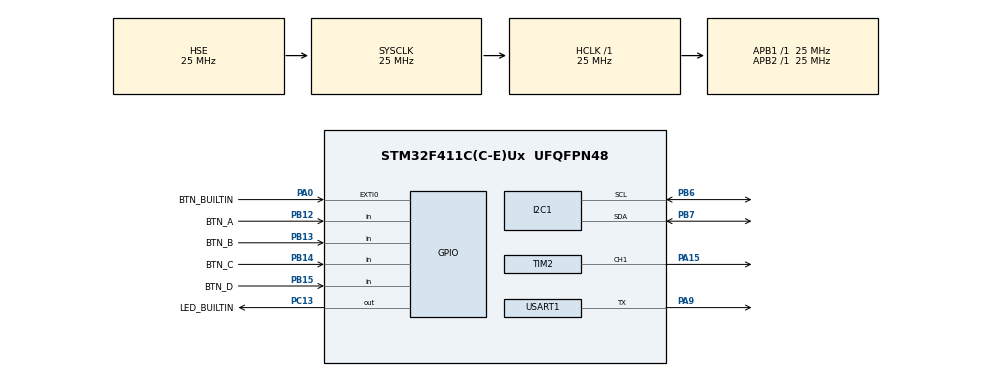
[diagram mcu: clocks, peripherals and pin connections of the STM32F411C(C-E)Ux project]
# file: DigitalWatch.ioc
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FREERTOS.INCLUDE_xTaskAbortDelay=1
FREERTOS.Tasks01=defaultTask,24,128,StartDefaultTask,Default,NULL,Dynamic,NULL,NULL
FREERTOS.configGENERATE_RUN_TIME_STATS=1
FREERTOS.configRECORD_STACK_HIGH_ADDRESS=1
FREERTOS.configTIMER_TASK_PRIORITY=4
FREERTOS.configTIMER_TASK_STACK_DEPTH=256
FREERTOS.configUSE_IDLE_HOOK=0
FREERTOS.configUSE_PREEMPTION=0
FREERTOS.configUSE_STATS_FORMATTING_FUNCTIONS=1
Mcu.Family=STM32F4
Mcu.Name=STM32F411C(C-E)Ux
Mcu.Package=UFQFPN48
NVIC.EXTI0_IRQn=true\:5\:0\:false\:false\:true\:true\:true\:true\:true
NVIC.PriorityGroup=NVIC_PRIORITYGROUP_4
NVIC.RTC_Alarm_IRQn=true\:5\:0\:true\:false\:true\:true\:true\:true\:true
NVIC.TIM1_TRG_COM_TIM11_IRQn=true\:15\:0\:false\:false\:true\:false\:false\:true\:true
NVIC.TimeBase=TIM1_TRG_COM_TIM11_IRQn
NVIC.TimeBaseIP=TIM11
PA0-WKUP.GPIO_Label=BTN_BUILTIN
PA0-WKUP.GPIO_ModeDefaultEXTI=GPIO_MODE_IT_FALLING
PA0-WKUP.GPIO_PuPd=GPIO_PULLUP
PA0-WKUP.Signal=GPXTI0
PA13.Mode=Serial_Wire
PA13.Signal=SYS_JTMS-SWDIO
PA14.Mode=Serial_Wire
PA14.Signal=SYS_JTCK-SWCLK
PA15.Signal=S_TIM2_CH1_ETR
PA9.Mode=Half_duplex(single_wire_mode)
PA9.Signal=USART1_TX
PB12.GPIO_Label=BTN_A
PB12.GPIO_PuPd=GPIO_PULLDOWN
PB12.Signal=GPIO_Input
PB13.GPIO_Label=BTN_B
PB13.GPIO_PuPd=GPIO_PULLDOWN
PB13.Signal=GPIO_Input
PB14.GPIO_Label=BTN_C
PB14.GPIO_PuPd=GPIO_PULLDOWN
PB14.Signal=GPIO_Input
PB15.GPIO_Label=BTN_D
PB15.GPIO_PuPd=GPIO_PULLDOWN
PB15.Signal=GPIO_Input
PB6.Mode=I2C
PB6.Signal=I2C1_SCL
PB7.Mode=I2C
PB7.Signal=I2C1_SDA
PC13-ANTI_TAMP.GPIO_Label=LED_BUILTIN
PC13-ANTI_TAMP.PinState=GPIO_PIN_SET
PC13-ANTI_TAMP.Signal=GPIO_Output
PC14-OSC32_IN.Mode=LSE-External-Oscillator
PC14-OSC32_IN.Signal=RCC_OSC32_IN
PC15-OSC32_OUT.Mode=LSE-External-Oscillator
PC15-OSC32_OUT.Signal=RCC_OSC32_OUT
PH0\ -\ OSC_IN.Mode=HSE-External-Oscillator
PH0\ -\ OSC_IN.Signal=RCC_OSC_IN
PH1\ -\ OSC_OUT.Mode=HSE-External-Oscillator
PH1\ -\ OSC_OUT.Signal=RCC_OSC_OUT
ProjectManager.HeapSize=0x200
ProjectManager.StackSize=0x400
ProjectManager.TargetToolchain=Makefile
RCC.AHBFreq_Value=25000000
RCC.APB1Freq_Value=25000000
RCC.APB1TimFreq_Value=25000000
RCC.APB2Freq_Value=25000000
RCC.APB2TimFreq_Value=25000000
RCC.CortexFreq_Value=25000000
RCC.HCLKFreq_Value=25000000
RCC.HSE_VALUE=25000000
RCC.HSI_VALUE=16000000
RCC.RCC_RTC_Clock_SourceVirtual=RCC_RTCCLKSOURCE_LSE
RCC.SYSCLKFreq_VALUE=25000000
RCC.SYSCLKSource=RCC_SYSCLKSOURCE_HSE
RCC.VCOOutputFreq_Value=192000000
RTC.Alarm=RTC_ALARM_A
RTC.AlarmDateWeekDay=RTC_WEEKDAY_MONDAY
RTC.AlarmDateWeekDaySel=RTC_ALARMDATEWEEKDAYSEL_WEEKDAY
RTC.AlarmMaskDateWeekDay=RTC_ALARMMASK_DATEWEEKDAY
RTC.AlarmMaskSeconds=RTC_ALARMMASK_SECONDS
RTC.Date=16
RTC.Format=RTC_FORMAT_BIN
RTC.HourFormat=RTC_HOURFORMAT_12
RTC.Hours=12
RTC.Hours_A=6
RTC.Month=RTC_MONTH_NOVEMBER
RTC.WeekDay=RTC_WEEKDAY_SATURDAY
RTC.Year=24
SH.S_TIM2_CH1_ETR.0=TIM2_CH1,PWM Generation1 CH1
TIM2.AutoReloadPreload=TIM_AUTORELOAD_PRELOAD_ENABLE
TIM2.Channel-PWM\ Generation1\ CH1=TIM_CHANNEL_1
TIM2.OCPolarity_1=TIM_OCPOLARITY_LOW
TIM2.Period=999
TIM2.Prescaler=24
TIM2.Pulse-PWM\ Generation1\ CH1=499
USART1.Mode=MODE_TX
USART1.VirtualMode=VM_ASYNC
VP_FREERTOS_VS_CMSIS_V2.Mode=CMSIS_V2
VP_RTC_VS_RTC_Activate.Mode=RTC_Enabled
VP_RTC_VS_RTC_Alarm_A_Intern.Mode=Alarm A
VP_RTC_VS_RTC_Calendar.Mode=RTC_Calendar
VP_SYS_VS_tim11.Mode=TIM11
VP_TIM2_VS_ClockSourceINT.Mode=Internal
board=custom

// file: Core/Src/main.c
/* USER CODE BEGIN Header */
/**
  ******************************************************************************
  * @file           : main.c
  * @brief          : Main program body
  ******************************************************************************
  * @attention
  *
  * Copyright (c) 2024 STMicroelectronics.
  * All rights reserved.
  *
  * This software is licensed under terms that can be found in the LICENSE file
  * in the root directory of this software component.
  * If no LICENSE file comes with this software, it is provided AS-IS.
  *
  ******************************************************************************
  */
/* USER CODE END Header */
#include "main.h"
#include "cmsis_os.h"
#include "i2c.h"
#include "rtc.h"
#include "tim.h"
#include "usart.h"
#include "gpio.h"

void SystemClock_Config(void);
void MX_FREERTOS_Init(void);

int main(void)
{

  /* MCU Configuration--------------------------------------------------------*/

  /* Reset of all peripherals, Initializes the Flash interface and the Systick. */
  HAL_Init();

  /* Configure the system clock */
  SystemClock_Config();

  /* Initialize all configured peripherals */
  MX_GPIO_Init();
  MX_RTC_Init();
  MX_USART1_UART_Init();
  MX_I2C1_Init();
  MX_TIM2_Init();
  /* USER CODE BEGIN 2 */
  App_Tasks_Init();

  /* USER CODE END 2 */

  /* Init scheduler */
  osKernelInitialize();  /* Call init function for freertos objects (in freertos.c) */
  MX_FREERTOS_Init();

  /* Start scheduler */
  osKernelStart();

  /* We should never get here as control is now taken by the scheduler */
  /* Infinite loop */
  while (1)
  {

  }
}

void SystemClock_Config(void)
{
  RCC_OscInitTypeDef RCC_OscInitStruct = {0};
  RCC_ClkInitTypeDef RCC_ClkInitStruct = {0};

  /** Configure the main internal regulator output voltage
  */
  __HAL_RCC_PWR_CLK_ENABLE();
  __HAL_PWR_VOLTAGESCALING_CONFIG(PWR_REGULATOR_VOLTAGE_SCALE1);

  /** Initializes the RCC Oscillators according to the specified parameters
  * in the RCC_OscInitTypeDef structure.
  */
  RCC_OscInitStruct.OscillatorType = RCC_OSCILLATORTYPE_HSE|RCC_OSCILLATORTYPE_LSE;
  RCC_OscInitStruct.HSEState = RCC_HSE_ON;
  RCC_OscInitStruct.LSEState = RCC_LSE_ON;
  RCC_OscInitStruct.PLL.PLLState = RCC_PLL_NONE;
  if (HAL_RCC_OscConfig(&RCC_OscInitStruct) != HAL_OK)
  {
    Error_Handler();
  }

  /** Initializes the CPU, AHB and APB buses clocks
  */
  RCC_ClkInitStruct.ClockType = RCC_CLOCKTYPE_HCLK|RCC_CLOCKTYPE_SYSCLK
                              |RCC_CLOCKTYPE_PCLK1|RCC_CLOCKTYPE_PCLK2;
  RCC_ClkInitStruct.SYSCLKSource = RCC_SYSCLKSOURCE_HSE;
  RCC_ClkInitStruct.AHBCLKDivider = RCC_SYSCLK_DIV1;
  RCC_ClkInitStruct.APB1CLKDivider = RCC_HCLK_DIV1;
  RCC_ClkInitStruct.APB2CLKDivider = RCC_HCLK_DIV1;

  if (HAL_RCC_ClockConfig(&RCC_ClkInitStruct, FLASH_LATENCY_0) != HAL_OK)
  {
    Error_Handler();
  }
}

void HAL_TIM_PeriodElapsedCallback(TIM_HandleTypeDef *htim)
{
  if (htim->Instance == TIM11) {
    HAL_IncTick();
  }
}

void Error_Handler(void)
{
  __disable_irq();
  while (1)
  {
  }
}

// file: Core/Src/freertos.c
/* USER CODE BEGIN Header */
/**
  ******************************************************************************
  * File Name          : freertos.c
  * Description        : Code for freertos applications
  ******************************************************************************
  * @attention
  *
  * Copyright (c) 2024 STMicroelectronics.
  * All rights reserved.
  *
  * This software is licensed under terms that can be found in the LICENSE file
  * in the root directory of this software component.
  * If no LICENSE file comes with this software, it is provided AS-IS.
  *
  ******************************************************************************
  */
/* USER CODE END Header */

#include "FreeRTOS.h"
#include "task.h"
#include "main.h"
#include "cmsis_os.h"

/* USER CODE BEGIN Variables */

extern TIM_HandleTypeDef                    htim11;                         /* externed from hal_timebase_tim.c */
extern volatile unsigned long               ulHighFrequencyTimerTicks;      /* externed from it.c */

/* USER CODE END Variables */
/* Definitions for defaultTask */
osThreadId_t defaultTaskHandle;
const osThreadAttr_t defaultTask_attributes = {
  .name = "defaultTask",
  .stack_size = 128 * 4,
  .priority = (osPriority_t) osPriorityNormal,
};

void StartDefaultTask(void *argument);

void MX_FREERTOS_Init(void); /* (MISRA C 2004 rule 8.1) */

/* Hook prototypes */
void configureTimerForRunTimeStats(void);
unsigned long getRunTimeCounterValue(void);

/* USER CODE BEGIN 1 */
/* Functions needed when configGENERATE_RUN_TIME_STATS is on */

void configureTimerForRunTimeStats(void)
{
  HAL_TIM_Base_Start_IT(&htim11);
}

unsigned long getRunTimeCounterValue(void)
{
  return ulHighFrequencyTimerTicks;
}
/* USER CODE END 1 */

void MX_FREERTOS_Init(void) {
/* USER CODE BEGIN Header */
/**
  ******************************************************************************
  * File Name          : freertos.c
  * Description        : Code for freertos applications
  ******************************************************************************
  * @attention
  *
  * Copyright (c) 2024 STMicroelectronics.
  * All rights reserved.
  *
  * This software is licensed under terms that can be found in the LICENSE file
  * in the root directory of this software component.
  * If no LICENSE file comes with this software, it is provided AS-IS.
  *
  ******************************************************************************
  */
/* USER CODE END Header */

}

void StartDefaultTask(void *argument)
{
  for(;;)
  {
    osDelay(1);
  }
}
